# MSP430FR5962 register map
File version: 2.1
CPU: MSP430FR5962 r2p1, little endian, MPU, no FPU, 3 interrupt priority bits
Registers are 16-bit, read-write, reset 0x0 unless marked. A register's access mark holds for its fields unless they carry their own. Offsets are from the block's base; [hi:lo] are bit positions; 'fields as' and 'values as' point back to an identical list.

## eUSCI_A2
Base 0x00000600
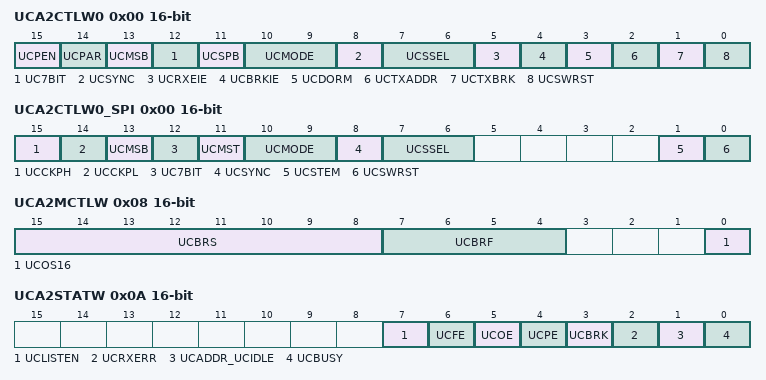
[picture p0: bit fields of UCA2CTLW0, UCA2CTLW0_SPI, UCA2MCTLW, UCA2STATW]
0x00 UCA2CTLW0 — eUSCI_Ax Control Word Register 0
  [15] UCPEN — [15:15] Parity enable
    0=Parity disabled; 1=Parity enabled. Parity bit is generated (UCAxTXD) and expected (UCAxRXD). In address-bit multiprocessor mode, the address bit is included in the parity calculation.
  [14] UCPAR — [14:14] Parity select
    0=ODD (Odd parity); 1=EVEN (Even parity)
  [13] UCMSB — [13:13] MSB first select
    0=LSB first; 1=MSB first
  [12] UC7BIT — [12:12] Character length
    0=8BIT (8-bit data); 1=7BIT (7-bit data)
  [11] UCSPB — [11:11] Stop bit select
    0=One stop bit; 1=Two stop bits
  [10:9] UCMODE — [10:9] eUSCI_A mode
    0=UART mode; 1=Idle-line multiprocessor mode; 2=Address-bit multiprocessor mode; 3=UART mode with automatic baud-rate detection
  [8] UCSYNC — [8:8] Synchronous mode enable
    0=ASYNC (Asynchronous mode); 1=SYNC (Synchronous mode)
  [7:6] UCSSEL — [7:6] eUSCI_A clock source select
    0=UCLK; 1=ACLK; 2=SMCLK
  [5] UCRXEIE — [5:5] Receive erroneous-character interrupt enable
    0=Erroneous characters rejected and UCRXIFG is not set; 1=Erroneous characters received set UCRXIFG
  [4] UCBRKIE — [4:4] Receive break character interrupt enable
    0=Received break characters do not set UCRXIFG; 1=Received break characters set UCRXIFG
  [3] UCDORM — [3:3] Dormant
    0=Not dormant. All received characters set UCRXIFG.; 1=Dormant. Only characters that are preceded by an idle-line or with address bit set UCRXIFG. In UART mode with automatic baud-rate detection, only the combination of a break and synch field sets UCRXIFG.
  [2] UCTXADDR — [2:2] Transmit address
    0=Next frame transmitted is data; 1=Next frame transmitted is an address
  [1] UCTXBRK — [1:1] Transmit break
    0=Next frame transmitted is not a break; 1=Next frame transmitted is a break or a break/synch
  [0] UCSWRST — [0:0] Software reset enable
    0=DISABLE (Disabled. eUSCI_A reset released for operation); 1=ENABLE (Enabled. eUSCI_A logic held in reset state)
0x00 UCA2CTLW0_SPI — eUSCI_Ax Control Word Register 0
  [15] UCCKPH — [15:15] Clock phase select
    0=Data is changed on the first UCLK edge and captured on the following edge; 1=Data is captured on the first UCLK edge and changed on the following edge
  [14] UCCKPL — [14:14] Clock polarity select
    0=LOW (The inactive state is low); 1=HIGH (The inactive state is high)
  [13] UCMSB — [13:13] MSB first select
    0=LSB first; 1=MSB first
  [12] UC7BIT — [12:12] Character length
    0=8BIT (8-bit data); 1=7BIT (7-bit data)
  [11] UCMST — [11:11] Master mode select
    0=SLAVE (Slave mode); 1=MASTER (Master mode)
  [10:9] UCMODE — [10:9] eUSCI mode
    0=3-pin SPI; 1=4-pin SPI with UCxSTE active high: Slave enabled when UCxSTE = 1; 2=4-pin SPI with UCxSTE active low: Slave enabled when UCxSTE = 0
  [8] UCSYNC — [8:8] Synchronous mode enable
    0=ASYNC (Asynchronous mode); 1=SYNC (Synchronous mode)
  [7:6] UCSSEL — [7:6] eUSCI_A clock source select
    1=ACLK; 2=SMCLK
  [1] UCSTEM — [1:1] STE mode select in master mode.
    0=STE pin is used to prevent conflicts with other masters; 1=STE pin is used to generate the enable signal for a 4-wire slave
  [0] UCSWRST — [0:0] Software reset enable
    values as UCA2CTLW0.UCSWRST
0x02 UCA2CTLW1 — eUSCI_Ax Control Word Register 1
  [1:0] UCGLIT — [1:0] Deglitch time
    0=Approximately 2 ns (equivalent of 1 delay element); 1=Approximately 50 ns; 2=Approximately 100 ns; 3=Approximately 200 ns
0x06 UCA2BRW — eUSCI_Ax Baud Rate Control Word Register
0x06 UCA2BRW_SPI — eUSCI_Ax Bit Rate Control Register 1
0x08 UCA2MCTLW — eUSCI_Ax Modulation Control Word Register
  [15:8] UCBRS — [15:8] Second modulation stage select
  [7:4] UCBRF — [7:4] First modulation stage select
  [0] UCOS16 — [0:0] Oversampling mode enabled
    0=Disabled; 1=Enabled
0x0A UCA2STATW — eUSCI_Ax Status Register
  [7] UCLISTEN — [7:7] Listen enable
    0=Disabled; 1=Enabled. UCAxTXD is internally fed back to the receiver
  [6] UCFE — [6:6] Framing error flag
    0=No error; 1=Character received with low stop bit
  [5] UCOE — [5:5] Overrun error flag
    0=No error; 1=Overrun error occurred
  [4] UCPE — [4:4] Parity error flag. When UCPEN = 0, UCPE is read as 0. UCPE is cleared when UCAxRXBUF is read.
    0=No error; 1=Character received with parity error
  [3] UCBRK — [3:3] Break detect flag
    0=No break condition; 1=Break condition occurred
  [2] UCRXERR — [2:2] Receive error flag
    0=No receive errors detected; 1=Receive error detected
  [1] UCADDR_UCIDLE — [1:1] Address received / Idle line detected
  [0] UCBUSY — [0:0] eUSCI_A busy
    0=IDLE (eUSCI_A inactive); 1=BUSY (eUSCI_A transmitting or receiving)
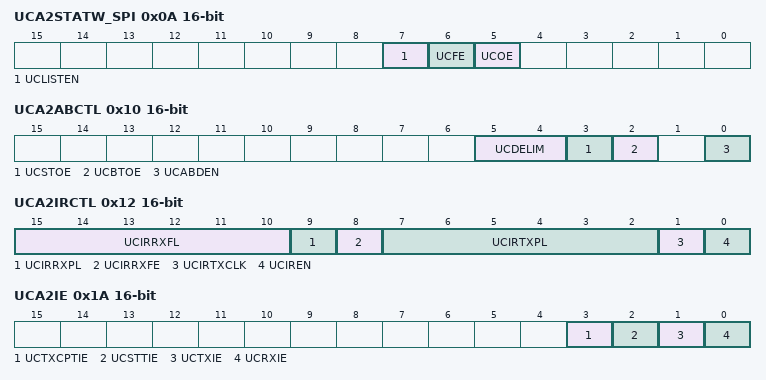
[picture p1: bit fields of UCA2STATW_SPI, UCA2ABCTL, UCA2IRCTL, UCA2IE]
0x0A UCA2STATW_SPI
  [7] UCLISTEN — [7:7] Listen enable
    values as UCA2STATW.UCLISTEN
  [6] UCFE — [6:6] Framing error flag
    0=No error; 1=Bus conflict occurred
  [5] UCOE — [5:5] Overrun error flag
    0=No error; 1=Overrun error occurred
0x0C UCA2RXBUF — eUSCI_Ax Receive Buffer Register
  [7:0] UCRXBUF — [7:0] Receive data buffer
0x0C UCA2RXBUF_SPI — eUSCI_Ax Receive Buffer Register
  [7:0] UCRXBUF — [7:0] Receive data buffer
0x0E UCA2TXBUF — eUSCI_Ax Transmit Buffer Register
  [7:0] UCTXBUF — [7:0] Transmit data buffer
0x0E UCA2TXBUF_SPI — eUSCI_Ax Transmit Buffer Register
  [7:0] UCTXBUF — [7:0] Transmit data buffer
0x10 UCA2ABCTL — eUSCI_Ax Auto Baud Rate Control Register
  [5:4] UCDELIM — [5:4] Break/synch delimiter length
    0=1 bit time; 1=2 bit times; 2=3 bit times; 3=4 bit times
  [3] UCSTOE — [3:3] Synch field time out error
    0=No error; 1=Length of synch field exceeded measurable time
  [2] UCBTOE — [2:2] Break time out error
    0=No error; 1=Length of break field exceeded 22 bit times
  [0] UCABDEN — [0:0] Automatic baud-rate detect enable
    0=Baud-rate detection disabled. Length of break and synch field is not measured.; 1=Baud-rate detection enabled. Length of break and synch field is measured and baud-rate settings are changed accordingly.
0x12 UCA2IRCTL — eUSCI_Ax IrDA Control Word Register
  [15:10] UCIRRXFL — [15:10] Receive filter length
  [9] UCIRRXPL — [9:9] IrDA receive input UCAxRXD polarity
    0=HIGH (IrDA transceiver delivers a high pulse when a light pulse is seen); 1=LOW (IrDA transceiver delivers a low pulse when a light pulse is seen)
  [8] UCIRRXFE — [8:8] IrDA receive filter enabled
    0=Receive filter disabled; 1=Receive filter enabled
  [7:2] UCIRTXPL — [7:2] Transmit pulse length
  [1] UCIRTXCLK — [1:1] IrDA transmit pulse clock select
    0=BRCLK; 1=BITCLK16 when UCOS16 = 1. Otherwise, BRCLK.
  [0] UCIREN — [0:0] IrDA encoder/decoder enable
    0=IrDA encoder/decoder disabled; 1=IrDA encoder/decoder enabled
0x1A UCA2IE — eUSCI_Ax Interrupt Enable Register
  [all] fields
    0=Interrupt disabled; 1=Interrupt enabled
  [3] UCTXCPTIE — [3:3] Transmit complete interrupt enable
  [2] UCSTTIE — [2:2] Start bit interrupt enable
  [1] UCTXIE — [1:1] Transmit interrupt enable
  [0] UCRXIE — [0:0] Receive interrupt enable
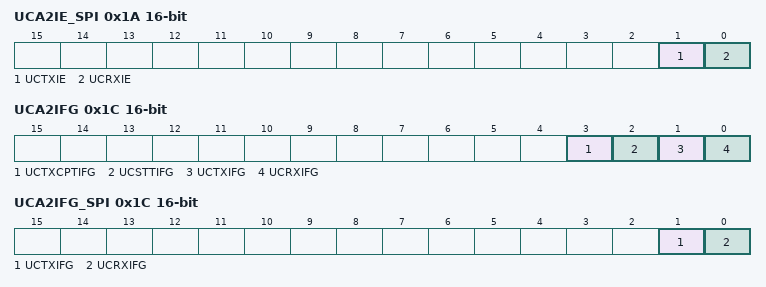
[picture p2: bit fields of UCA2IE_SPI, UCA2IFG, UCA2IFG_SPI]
0x1A UCA2IE_SPI — eUSCI_Ax Interrupt Enable Register
  [1] UCTXIE — [1:1] Transmit interrupt enable
    0=Interrupt disabled; 1=Interrupt enabled
  [0] UCRXIE — [0:0] Receive interrupt enable
    0=Interrupt disabled; 1=Interrupt enabled
0x1C UCA2IFG — eUSCI_Ax Interrupt Flag Register
  [all] fields
    0=No interrupt pending; 1=Interrupt pending
  [3] UCTXCPTIFG — [3:3] Transmit ready interrupt enable
  [2] UCSTTIFG — [2:2] Start bit interrupt flag
  [1] UCTXIFG — [1:1] Transmit interrupt flag
  [0] UCRXIFG — [0:0] Receive interrupt flag
0x1C UCA2IFG_SPI — eUSCI_Ax Interrupt Flag Register
  [1] UCTXIFG — [1:1] Transmit interrupt flag
    0=No interrupt pending; 1=Interrupt pending
  [0] UCRXIFG — [0:0] Receive interrupt flag
    0=No interrupt pending; 1=Interrupt pending
0x1E UCA2IV — eUSCI_Ax Interrupt Vector Register
  [15:0] UCIV — [15:0] eUSCI_A interrupt vector value
    0=NONE (No interrupt pending); 2=UCRXIFG (Interrupt Source: Receive buffer full; Interrupt Flag: UCRXIFG; Interrupt Priority: Highest); 4=UCTXIFG (Interrupt Source: Transmit buffer empty; Interrupt Flag: UCTXIFG); 6=UCSTTIFG (Interrupt Source: Start bit received; Interrupt Flag: UCSTTIFG); 8=UCTXCPTIFG (Interrupt Source: Transmit complete; Interrupt Flag: UCTXCPTIFG; Interrupt Priority: Lowest)
0x1E UCA2IV_SPI — eUSCI_Ax Interrupt Vector Register
  [15:0] UCIV — [15:0] eUSCI_A interrupt vector value
    0=NONE (No interrupt pending); 2=UCRXIFG (Interrupt Source: Data received; Interrupt Flag: UCRXIFG; Interrupt Priority: Highest); 4=UCTXIFG (Interrupt Source: Transmit buffer empty; Interrupt Flag: UCTXIFG; Interrupt Priority: Lowest)
